VERSION "Hyundai Custin 1st gen front radar, reverse engineered from own-car rlog 2026-08"

NS_ :

BS_:

BU_: XXX RADAR

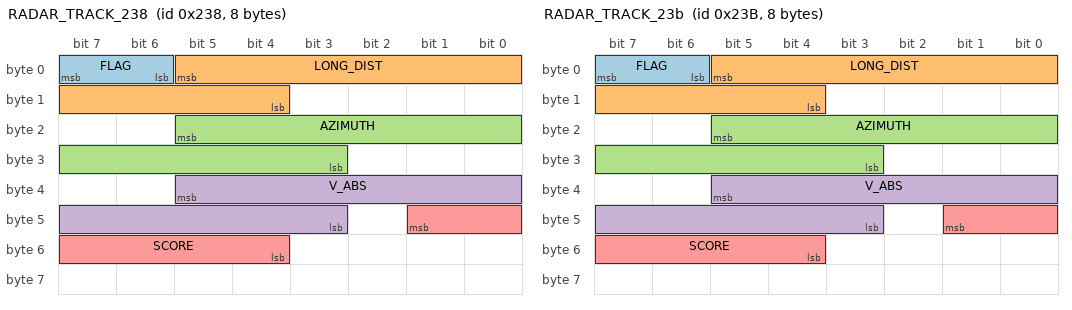
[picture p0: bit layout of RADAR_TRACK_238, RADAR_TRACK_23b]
BO_ 568 RADAR_TRACK_238: 8 RADAR
 SG_ FLAG : 7|2@0+ (1,0) [0|3] "" XXX
 SG_ LONG_DIST : 5|10@0+ (0.1,0) [0|102.3] "m" XXX
 SG_ AZIMUTH : 21|11@0- (0.0538,0) [-55.0912|55.0374] "deg" XXX
 SG_ V_ABS : 37|11@0- (0.02526,2.587) [-23.2792|28.428] "m/s" XXX
 SG_ SCORE : 41|6@0+ (1,0) [0|63] "" XXX

BO_ 571 RADAR_TRACK_23b: 8 RADAR
 SG_ FLAG : 7|2@0+ (1,0) [0|3] "" XXX
 SG_ LONG_DIST : 5|10@0+ (0.1,0) [0|102.3] "m" XXX
 SG_ AZIMUTH : 21|11@0- (0.0538,0) [-55.0912|55.0374] "deg" XXX
 SG_ V_ABS : 37|11@0- (0.02526,2.587) [-23.2792|28.428] "m/s" XXX
 SG_ SCORE : 41|6@0+ (1,0) [0|63] "" XXX

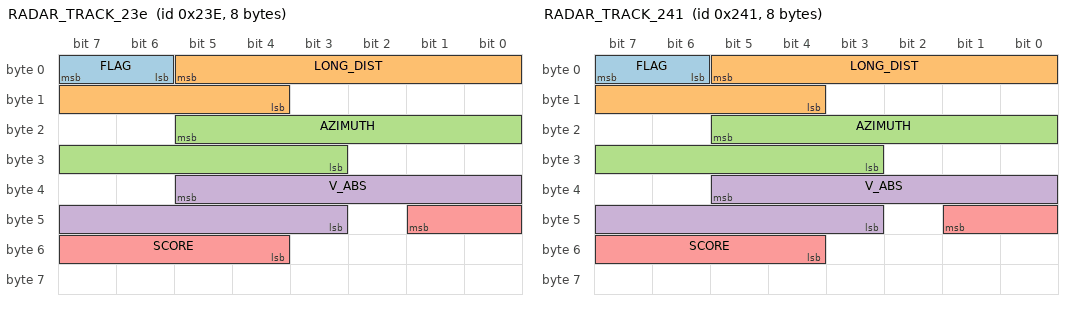
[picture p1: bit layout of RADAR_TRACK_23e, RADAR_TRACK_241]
BO_ 574 RADAR_TRACK_23e: 8 RADAR
 SG_ FLAG : 7|2@0+ (1,0) [0|3] "" XXX
 SG_ LONG_DIST : 5|10@0+ (0.1,0) [0|102.3] "m" XXX
 SG_ AZIMUTH : 21|11@0- (0.0538,0) [-55.0912|55.0374] "deg" XXX
 SG_ V_ABS : 37|11@0- (0.02526,2.587) [-23.2792|28.428] "m/s" XXX
 SG_ SCORE : 41|6@0+ (1,0) [0|63] "" XXX

BO_ 577 RADAR_TRACK_241: 8 RADAR
 SG_ FLAG : 7|2@0+ (1,0) [0|3] "" XXX
 SG_ LONG_DIST : 5|10@0+ (0.1,0) [0|102.3] "m" XXX
 SG_ AZIMUTH : 21|11@0- (0.0538,0) [-55.0912|55.0374] "deg" XXX
 SG_ V_ABS : 37|11@0- (0.02526,2.587) [-23.2792|28.428] "m/s" XXX
 SG_ SCORE : 41|6@0+ (1,0) [0|63] "" XXX

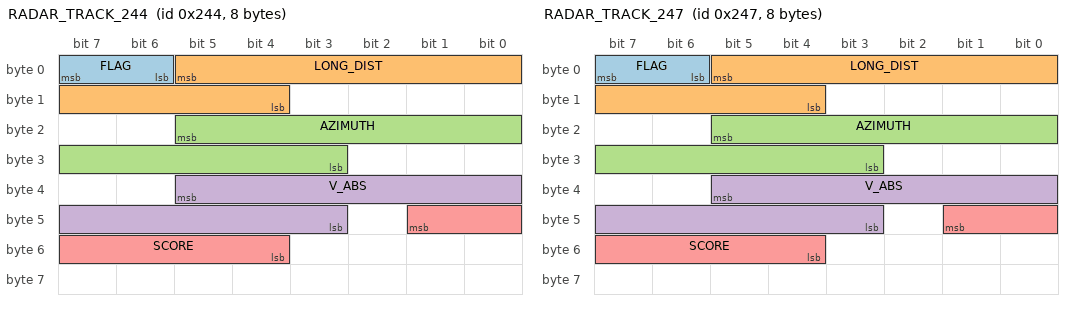
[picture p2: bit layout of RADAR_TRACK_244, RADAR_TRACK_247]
BO_ 580 RADAR_TRACK_244: 8 RADAR
 SG_ FLAG : 7|2@0+ (1,0) [0|3] "" XXX
 SG_ LONG_DIST : 5|10@0+ (0.1,0) [0|102.3] "m" XXX
 SG_ AZIMUTH : 21|11@0- (0.0538,0) [-55.0912|55.0374] "deg" XXX
 SG_ V_ABS : 37|11@0- (0.02526,2.587) [-23.2792|28.428] "m/s" XXX
 SG_ SCORE : 41|6@0+ (1,0) [0|63] "" XXX

BO_ 583 RADAR_TRACK_247: 8 RADAR
 SG_ FLAG : 7|2@0+ (1,0) [0|3] "" XXX
 SG_ LONG_DIST : 5|10@0+ (0.1,0) [0|102.3] "m" XXX
 SG_ AZIMUTH : 21|11@0- (0.0538,0) [-55.0912|55.0374] "deg" XXX
 SG_ V_ABS : 37|11@0- (0.02526,2.587) [-23.2792|28.428] "m/s" XXX
 SG_ SCORE : 41|6@0+ (1,0) [0|63] "" XXX

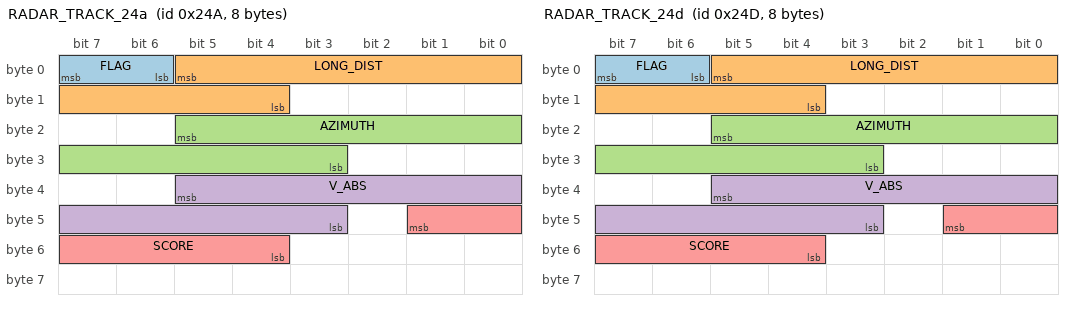
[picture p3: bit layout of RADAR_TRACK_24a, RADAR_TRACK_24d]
BO_ 586 RADAR_TRACK_24a: 8 RADAR
 SG_ FLAG : 7|2@0+ (1,0) [0|3] "" XXX
 SG_ LONG_DIST : 5|10@0+ (0.1,0) [0|102.3] "m" XXX
 SG_ AZIMUTH : 21|11@0- (0.0538,0) [-55.0912|55.0374] "deg" XXX
 SG_ V_ABS : 37|11@0- (0.02526,2.587) [-23.2792|28.428] "m/s" XXX
 SG_ SCORE : 41|6@0+ (1,0) [0|63] "" XXX

BO_ 589 RADAR_TRACK_24d: 8 RADAR
 SG_ FLAG : 7|2@0+ (1,0) [0|3] "" XXX
 SG_ LONG_DIST : 5|10@0+ (0.1,0) [0|102.3] "m" XXX
 SG_ AZIMUTH : 21|11@0- (0.0538,0) [-55.0912|55.0374] "deg" XXX
 SG_ V_ABS : 37|11@0- (0.02526,2.587) [-23.2792|28.428] "m/s" XXX
 SG_ SCORE : 41|6@0+ (1,0) [0|63] "" XXX

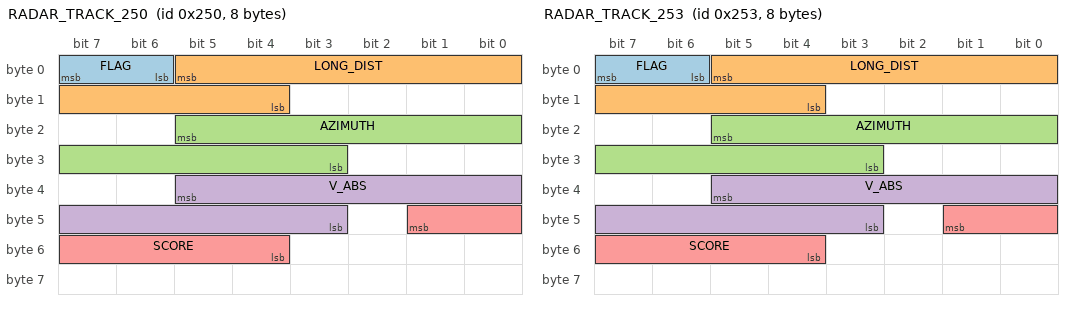
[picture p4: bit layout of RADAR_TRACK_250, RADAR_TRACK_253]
BO_ 592 RADAR_TRACK_250: 8 RADAR
 SG_ FLAG : 7|2@0+ (1,0) [0|3] "" XXX
 SG_ LONG_DIST : 5|10@0+ (0.1,0) [0|102.3] "m" XXX
 SG_ AZIMUTH : 21|11@0- (0.0538,0) [-55.0912|55.0374] "deg" XXX
 SG_ V_ABS : 37|11@0- (0.02526,2.587) [-23.2792|28.428] "m/s" XXX
 SG_ SCORE : 41|6@0+ (1,0) [0|63] "" XXX

BO_ 595 RADAR_TRACK_253: 8 RADAR
 SG_ FLAG : 7|2@0+ (1,0) [0|3] "" XXX
 SG_ LONG_DIST : 5|10@0+ (0.1,0) [0|102.3] "m" XXX
 SG_ AZIMUTH : 21|11@0- (0.0538,0) [-55.0912|55.0374] "deg" XXX
 SG_ V_ABS : 37|11@0- (0.02526,2.587) [-23.2792|28.428] "m/s" XXX
 SG_ SCORE : 41|6@0+ (1,0) [0|63] "" XXX
